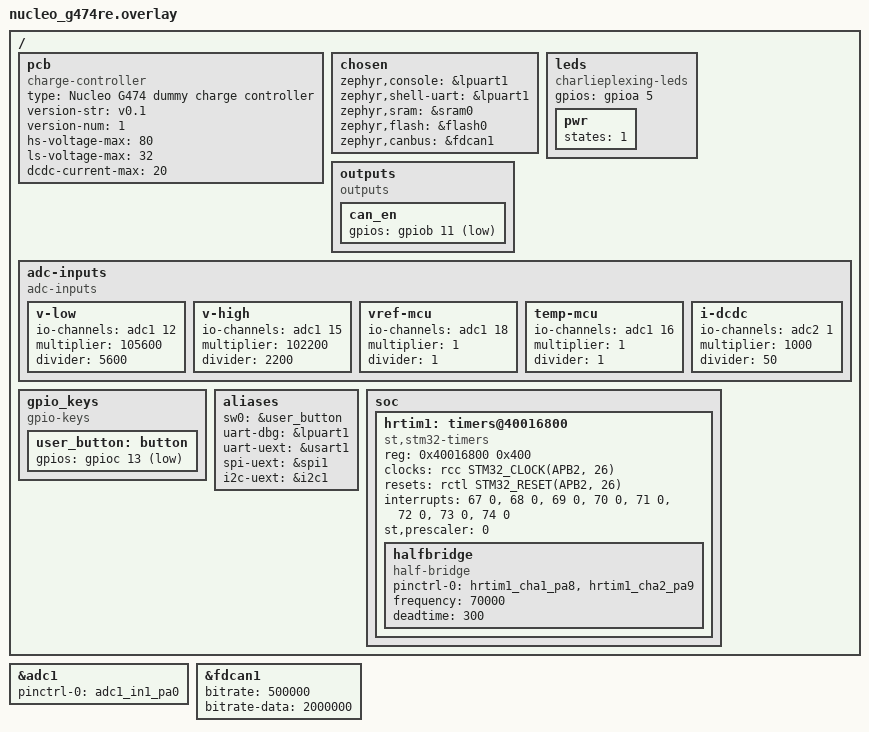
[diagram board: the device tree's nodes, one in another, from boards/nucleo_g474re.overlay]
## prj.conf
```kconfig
# Main application configuration (overrides board-specific settings)

# only very small heap necessary for malloc in printf statements with %f
CONFIG_HEAP_MEM_POOL_SIZE=256

CONFIG_CPP=y
CONFIG_REQUIRES_FULL_LIBCPP=y

CONFIG_PICOLIBC_IO_FLOAT=y

CONFIG_WATCHDOG=y
CONFIG_TASK_WDT=y
CONFIG_THREAD_NAME=y

CONFIG_REBOOT=y

CONFIG_HWINFO=y

CONFIG_CRC=y

CONFIG_CONSOLE_SUBSYS=y
CONFIG_CONSOLE_GETCHAR=y

# Use minimal logging by default to save memory for STM32F0 with little RAM
CONFIG_LOG=y
CONFIG_LOG_MODE_MINIMAL=y

CONFIG_THINGSET=y
CONFIG_THINGSET_SDK=y
CONFIG_THINGSET_STORAGE=y
CONFIG_THINGSET_SERIAL=y
CONFIG_THINGSET_STORAGE_DATA_VERSION=6
CONFIG_THINGSET_NODE_NAME="Libre Solar MPPT"

# Must be lower than LED thread to avoid flickering in boards with charlieplexing
CONFIG_THINGSET_SDK_THREAD_PRIORITY=6

# Uncomment to disable regular data publication on ThingSet serial at startup
#CONFIG_THINGSET_REPORTING_LIVE_ENABLE_PRESET=n

# Uncomment to enable I2C OLED display in UEXT connector
#CONFIG_UEXT_OLED_DISPLAY=y

# Select initial battery configuration: GEL (default), FLOODED, AGM, LFP, NMC or NMC_HV
#CONFIG_BAT_TYPE_???=y

# Change number of cells considering selected type (12V/24V battery by default if not set)
#CONFIG_BAT_NUM_CELLS=?
```

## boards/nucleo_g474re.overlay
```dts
/*
 * Copyright (c) 2019 STMicroelectronics.
 *
 * SPDX-License-Identifier: Apache-2.0
 */

/*
 * This is a dummy charge controller board for testing new features using the STM32G474 MCU
 *
 * IMPORTANT: You have to remove the VREF jumper on the Nucleo board to make it work. Otherwise
 *            the MCU will get stuck while trying to generate a reference voltage at VREF+ pin.
 */

/ {
	/* delete conflicting nodes from Zephyr board */
	/delete-node/ leds;
	/delete-node/ aliases;

	pcb {
		compatible = "charge-controller";

		type = "Nucleo G474 dummy charge controller";
		version-str = "v0.1";
		version-num = <1>;

		hs-voltage-max = <80>;
		ls-voltage-max = <32>;
		dcdc-current-max = <20>;
	};

	chosen {
		zephyr,console = &lpuart1;
		zephyr,shell-uart = &lpuart1;
		zephyr,sram = &sram0;
		zephyr,flash = &flash0;
		zephyr,canbus = &fdcan1;
	};

	leds {
		compatible = "charlieplexing-leds";
		gpios = <&gpioa 5 GPIO_ACTIVE_HIGH>;

		pwr {
			states = <1>;
		};
	};

	outputs {
		compatible = "outputs";

		can_en {
			gpios = <&gpiob 11 GPIO_ACTIVE_LOW>;
		};
	};

	adc-inputs {
		compatible = "adc-inputs";

		v-low {
			io-channels = <&adc1 12>;
			multiplier = <105600>;
			divider = <5600>;
		};

		v-high {
			io-channels = <&adc1 15>;
			multiplier = <102200>;
			divider = <2200>;
		};

		vref-mcu {
			io-channels = <&adc1 18>;
			multiplier = <1>;
			divider = <1>;
		};

		temp-mcu {
			io-channels = <&adc1 16>;
			multiplier = <1>;
			divider = <1>;
		};

		i-dcdc {
			io-channels = <&adc2 1>;
			// amp gain: 25, resistor: 2 mOhm
			multiplier = <1000>;	// 1000
			divider = <50>;	// 2*25
		};
	};

	gpio_keys {
		compatible = "gpio-keys";
		user_button: button {
			gpios = <&gpioc 13 GPIO_ACTIVE_LOW>;
		};
	};

	aliases {
		sw0 = &user_button;
		uart-dbg = &lpuart1;
		uart-uext = &usart1;
		spi-uext = &spi1;
		i2c-uext = &i2c1;
	};

	soc {
		hrtim1: timers@40016800 {
			compatible = "st,stm32-timers";
			reg = <0x40016800 0x400>;
			clocks = <&rcc STM32_CLOCK(APB2, 26)>;
			resets = <&rctl STM32_RESET(APB2, 26)>;
			interrupts = <67 0>, <68 0>, <69 0>, <70 0>,
				     <71 0>, <72 0>, <73 0>, <74 0>;
			interrupt-names = "master", "tima", "timb", "timc",
					  "timd", "time", "flt", "timf";
			st,prescaler = <0>;
			status = "disabled";
		};
	};
};

&hrtim1 {
	status = "okay";

	halfbridge: halfbridge {
		compatible = "half-bridge";
		pinctrl-0 = <&hrtim1_cha1_pa8 &hrtim1_cha2_pa9>;
		pinctrl-names = "default";
		frequency = <70000>;
		deadtime = <300>;
	};
};

/*
// alternative to HRTIM
&timers1 {
	status = "okay";

	halfbridge: halfbridge {
		compatible = "half-bridge";
		pinctrl-0 = <&tim1_ch1_pa8 &tim1_ch1n_pb13>;
		pinctrl-names = "default";
		frequency = <70000>;
		deadtime = <300>;
	};
};
*/

&adc1 {
	pinctrl-0 = <&adc1_in1_pa0>;
	pinctrl-names = "default";
	status = "okay";
};

&fdcan1 {
	bitrate = <500000>;
	bitrate-data = <2000000>;
	status = "okay";
};
```

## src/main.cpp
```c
/*
 * Copyright (c) The Libre Solar Project Contributors
 *
 * SPDX-License-Identifier: Apache-2.0
 */

#ifndef UNIT_TEST

#include <stdio.h>
#include <zephyr/device.h>
#include <zephyr/drivers/gpio.h>
#include <zephyr/kernel.h>
#include <zephyr/task_wdt/task_wdt.h>

#include "helper.h"
#include "setup.h"
#include "thingset.h" // handles access to internal data via communication interfaces

#include "bat_charger.h"   // battery settings and charger state machine
#include "daq.h"           // ADC using DMA and conversion to measurement values
#include "data_objects.h"  // for access to internal data via ThingSet
#include "data_storage.h"  // non-volatile data storage (e.g. EEPROM)
#include "dcdc.h"          // DC/DC converter control (hardware independent)
#include "device_status.h" // log data (error memory, min/max measurements, etc.)
#include "half_bridge.h"   // PWM generation for DC/DC converter
#include "hardware.h"   // hardware-related functions like load switch, LED control, watchdog, etc.
#include "leds.h"       // LED switching using charlieplexing
#include "load.h"       // load and USB output management
#include "pwm_switch.h" // PWM charge controller

int main(void)
{
    printf("Hardware: Libre Solar %s (%s)\n", DT_PROP(DT_PATH(pcb), type),
           DT_PROP(DT_PATH(pcb), version_str));
    printf("Firmware: %s\n", FIRMWARE_VERSION_ID);

    task_wdt_init(DEVICE_DT_GET_OR_NULL(DT_NODELABEL(iwdg)));

    setup();

    battery_conf_init(&bat_conf, CONFIG_BAT_TYPE, CONFIG_BAT_NUM_CELLS, CONFIG_BAT_CAPACITY_AH);
    battery_conf_overwrite(&bat_conf, &bat_conf_user); // initialize conf_user with same values

#if BOARD_HAS_DCDC
    daq_set_hv_limit(DT_PROP(DT_PATH(pcb), hs_voltage_max));
#endif

#if CONFIG_HV_TERMINAL_SOLAR || CONFIG_LV_TERMINAL_SOLAR || CONFIG_PWM_TERMINAL_SOLAR
    solar_terminal.init_solar();
#endif

#if CONFIG_HV_TERMINAL_NANOGRID
    grid_terminal.init_nanogrid();
#endif

    // read custom configuration from EEPROM
    data_objects_init();

    // Data Acquisition (DAQ) setup
    daq_setup();

    charger.detect_num_batteries(&bat_conf); // check if we have 24V instead of 12V system
    charger.init_terminal(&bat_conf);

#if BOARD_HAS_LOAD_OUTPUT
    load.set_voltage_limits(bat_conf.load_disconnect_voltage, bat_conf.load_reconnect_voltage,
                            bat_conf.absolute_max_voltage);
#endif

#if BOARD_HAS_USB_OUTPUT
    usb_pwr.set_voltage_limits(bat_conf.load_disconnect_voltage - 0.1f, // keep on longer than load
                               bat_conf.load_reconnect_voltage, bat_conf.absolute_max_voltage);
#endif

    // wait until all threads are spawned before activating the watchdog
    k_sleep(K_MSEC(2500));

    int64_t t_start = k_uptime_get();

    while (true) {
        // loop runs exactly once per second and includes slow control tasks and energy calculation

        charger.discharge_control(&bat_conf);
        charger.charge_control(&bat_conf);

// energy + soc calculation must be called exactly once per second
#if BOARD_HAS_DCDC
        if (dcdc.state != DCDC_CONTROL_OFF) {
            hv_terminal.energy_balance();
        }
#endif

#if BOARD_HAS_PWM_PORT
        if (pwm_switch.active() == 1) {
            pwm_switch.energy_balance();
        }
#endif

        lv_terminal.energy_balance();

#if BOARD_HAS_LOAD_OUTPUT
        if (load.state == 1) {
            load.energy_balance();
        }
#endif

        dev_stat.update_energy();
        dev_stat.update_min_max_values();
        charger.update_soc(&bat_conf);

#if CONFIG_HS_MOSFET_FAIL_SAFE_PROTECTION && BOARD_HAS_DCDC
        if (dev_stat.has_error(ERR_DCDC_HS_MOSFET_SHORT)) {
            dcdc.fuse_destruction();
        }
#endif

        leds_update_1s();

#if BOARD_HAS_LOAD_OUTPUT
        leds_update_soc(charger.soc, flags_check(&load.error_flags, ERR_LOAD_SHEDDING));
#else
        leds_update_soc(charger.soc, false);
#endif

        data_storage_update();

        t_start += 1000;
        k_sleep(K_TIMEOUT_ABS_MS(t_start));
    }
}

void control_thread()
{
    int wdt_channel = task_wdt_add(200, task_wdt_callback, (void *)k_current_get());

    while (true) {
        // control loop runs at approx. 10 Hz

        bool charging = false;

        task_wdt_feed(wdt_channel);

        // convert ADC readings to meaningful measurement values
        daq_update();

        // alerts should trigger only for transients, so update based on actual voltage
        daq_set_lv_limits(lv_terminal.bus->voltage * 1.2F, lv_terminal.bus->voltage * 0.8F);

        lv_terminal.update_bus_current_margins();

#if BOARD_HAS_PWM_PORT
        pwm_switch.control();
        charging |= pwm_switch.active();
#endif

#if BOARD_HAS_DCDC
        hv_terminal.update_bus_current_margins();
        dcdc.control(); // control of DC/DC including MPPT algorithm
        charging |= half_bridge_enabled();
#endif

        leds_set_charging(charging);

#if BOARD_HAS_LOAD_OUTPUT
        load.control();
#endif

#if BOARD_HAS_USB_OUTPUT
        usb_pwr.control();
#endif

        k_sleep(K_MSEC(100));
    }
}

// 2s delay for control thread as a safety feature: be able to re-flash before starting
// priority is set to -1 (=cooperative) to have higher priority than other threads incl. main
K_THREAD_DEFINE(control_thread_id, 1024, control_thread, NULL, NULL, NULL, -1, 0, 2000);

#endif // UNIT_TEST
```

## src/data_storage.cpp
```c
/*
 * Copyright (c) The Libre Solar Project Contributors
 *
 * SPDX-License-Identifier: Apache-2.0
 */

#include "data_storage.h"

#include <zephyr/kernel.h>

#include "data_objects.h"
#include "helper.h"
#include "mcu.h"
#include "thingset.h"
#include "zephyr/toolchain.h"

#include <stdio.h>

#ifdef CONFIG_SOC_FAMILY_STM32

#include <stm32_ll_bus.h>
#include <zephyr/device.h>

LOG_MODULE_REGISTER(nvs, CONFIG_DATA_STORAGE_LOG_LEVEL);

K_MUTEX_DEFINE(data_buf_lock);

// Buffer used by store and restore functions (must be word-aligned for hardware CRC calculation)
__maybe_unused static uint8_t buf[512] __aligned(sizeof(uint32_t));

extern ThingSet ts;

uint32_t _calc_crc(const uint8_t *buf, size_t len)
{
    LL_AHB1_GRP1_EnableClock(LL_AHB1_GRP1_PERIPH_CRC);

    // we keep standard polynomial 0x04C11DB7 (same for STM32L0 and STM32F0)
    // and we don't care for endianness here
    CRC->CR |= CRC_CR_RESET;
    for (size_t i = 0; i < len; i += 4) {
        // printf("CRC buf: %.8x, CRC->DR: %.8x\n", *((uint32_t*)&buf[i]), CRC->DR);
        size_t remaining_bytes = len - i;
        if (remaining_bytes >= 4) {
            CRC->DR = *((uint32_t *)&buf[i]);
        }
        else {
            // ignore bytes >= len if len is not a multiple of 4
            CRC->DR = *((uint32_t *)&buf[i]) & (0xFFFFFFFFU >> (32 - remaining_bytes * 8));
        }
    }

    LL_AHB1_GRP1_DisableClock(LL_AHB1_GRP1_PERIPH_CRC);

    return CRC->DR;
}

#endif /* UNIT_TEST */

#ifdef CONFIG_EEPROM

#include <zephyr/drivers/eeprom.h>

/*
 * EEPROM header bytes:
 * - 0-1: Data objects version number
 * - 2-3: Number of data bytes
 * - 4-7: CRC32
 *
 * Data starts from byte 8
 */
#define EEPROM_HEADER_SIZE 8

static const struct device *eeprom_dev = DEVICE_DT_GET(DT_NODELABEL(eeprom));

void data_storage_read()
{
    int err;

    if (!device_is_ready(eeprom_dev)) {
        LOG_ERR("EEPROM device not ready");
        return;
    }

    uint8_t buf_header[EEPROM_HEADER_SIZE] = {};
    err = eeprom_read(eeprom_dev, 0, buf_header, EEPROM_HEADER_SIZE);
    if (err != 0) {
        LOG_ERR("EEPROM read error %d", err);
        return;
    }
    uint16_t version = *((uint16_t *)&buf_header[0]);
    uint16_t len = *((uint16_t *)&buf_header[2]);
    uint32_t crc = *((uint32_t *)&buf_header[4]);

    LOG_DBG("EEPROM header restore: ver %d, len %d, CRC %.8x", version, len, (unsigned int)crc);
    LOG_DBG("Header: %.2x %.2x %.2x %.2x %.2x %.2x %.2x %.2x", buf_header[0], buf_header[1],
            buf_header[2], buf_header[3], buf_header[4], buf_header[5], buf_header[6],
            buf_header[7]);

    if (version == DATA_OBJECTS_VERSION && len <= sizeof(buf)) {
        k_mutex_lock(&data_buf_lock, K_FOREVER);
        err = eeprom_read(eeprom_dev, EEPROM_HEADER_SIZE, buf, len);

        // printf("Data (len=%d): ", len);
        // for (int i = 0; i < len; i++) printf("%.2x ", buf[i]);

        if (_calc_crc(buf, len) == crc) {
            int status = ts.bin_import(buf, sizeof(buf), TS_WRITE_MASK, SUBSET_NVM);
            LOG_INF("EEPROM read and data objects updated, ThingSet result: 0x%x", status);
        }
        else {
            LOG_ERR("EEPROM data CRC invalid, expected 0x%x (data_len = %d)", (unsigned int)crc,
                    len);
        }
        k_mutex_unlock(&data_buf_lock);
    }
    else {
        LOG_INF("EEPROM empty or data layout version changed");
    }
}

void data_storage_write()
{
    int err;

    if (!device_is_ready(eeprom_dev)) {
        LOG_ERR("EEPROM device not ready");
        return;
    }

    k_mutex_lock(&data_buf_lock, K_FOREVER);

    int len = ts.bin_export(buf + EEPROM_HEADER_SIZE, sizeof(buf) - EEPROM_HEADER_SIZE, SUBSET_NVM);
    uint32_t crc = _calc_crc(buf + EEPROM_HEADER_SIZE, len);

    *((uint16_t *)&buf[0]) = (uint16_t)DATA_OBJECTS_VERSION;
    *((uint16_t *)&buf[2]) = (uint16_t)(len);
    *((uint32_t *)&buf[4]) = crc;

    // printf("Data (len=%d): ", len);
    // for (int i = 0; i < len; i++) printf("%.2x ", buf[i + EEPROM_HEADER_SIZE]);

    LOG_DBG("Header: %.2x %.2x %.2x %.2x %.2x %.2x %.2x %.2x", buf[0], buf[1], buf[2], buf[3],
            buf[4], buf[5], buf[6], buf[7]);

    if (len == 0) {
        LOG_ERR("EEPROM data could not be stored. ThingSet error (len = %d)", len);
    }
    else {
        err = eeprom_write(eeprom_dev, 0, buf, len + EEPROM_HEADER_SIZE);
        if (err == 0) {
            LOG_INF("EEPROM data successfully stored");
        }
        else {
            LOG_ERR("EEPROM write error %d", err);
        }
    }
    k_mutex_unlock(&data_buf_lock);
}

#elif defined(CONFIG_NVS)

#include <zephyr/drivers/flash.h>
#include <zephyr/fs/nvs.h>
#include <zephyr/storage/flash_map.h>

/*
 * NVS header bytes:
 * - 0-1: Data objects version number
 *
 * Data starts from byte 2
 */
#define NVS_HEADER_SIZE 2

#define NVS_PARTITION storage_partition

#define THINGSET_DATA_ID 1

static struct nvs_fs fs;
static bool nvs_initialized = false;

static int data_storage_init()
{
    int err;
    struct flash_pages_info page_info;

    fs.flash_device = FIXED_PARTITION_DEVICE(NVS_PARTITION);
    if (!device_is_ready(fs.flash_device)) {
        LOG_ERR("Flash device not ready");
        return -ENODEV;
    }
    fs.offset = FIXED_PARTITION_OFFSET(NVS_PARTITION);
    err = flash_get_page_info_by_offs(fs.flash_device, fs.offset, &page_info);
    if (err) {
        LOG_ERR("Unable to get flash page info");
        return err;
    }
    fs.sector_size = page_info.size;
    fs.sector_count = FIXED_PARTITION_SIZE(NVS_PARTITION) / page_info.size;

    err = nvs_mount(&fs);
    if (err) {
        LOG_ERR("NVS mount failed: %d", err);
        return err;
    }

    nvs_initialized = true;
    return 0;
}

void data_storage_read()
{
    if (!nvs_initialized) {
        int err = data_storage_init();
        if (err) {
            return;
        }
    }

    int num_bytes = nvs_read(&fs, THINGSET_DATA_ID, &buf, sizeof(buf));

    if (num_bytes < 0) {
        LOG_INF("NVS empty (read error %d)", num_bytes);
        return;
    }

    uint16_t version = *((uint16_t *)&buf[0]);

    if (version == DATA_OBJECTS_VERSION) {
        k_mutex_lock(&data_buf_lock, K_FOREVER);

        int status = ts.bin_import(buf + NVS_HEADER_SIZE, num_bytes - NVS_HEADER_SIZE,
                                   TS_WRITE_MASK, SUBSET_NVM);
        LOG_INF("NVS read and data objects updated, ThingSet result: 0x%x", status);

        k_mutex_unlock(&data_buf_lock);
    }
    else {
        LOG_INF("NVS data layout version changed");
    }
}

void data_storage_write()
{
    if (!nvs_initialized) {
        int err = data_storage_init();
        if (err) {
            return;
        }
    }

    k_mutex_lock(&data_buf_lock, K_FOREVER);

    *((uint16_t *)&buf[0]) = (uint16_t)DATA_OBJECTS_VERSION;

    int len = ts.bin_export(buf + NVS_HEADER_SIZE, sizeof(buf) - NVS_HEADER_SIZE, SUBSET_NVM);

    if (len == 0) {
        LOG_ERR("NVS data could not be stored. ThingSet error (len = %d)", len);
    }
    else {
        int ret = nvs_write(&fs, THINGSET_DATA_ID, &buf, len + NVS_HEADER_SIZE);
        if (ret == len + NVS_HEADER_SIZE) {
            LOG_DBG("NVS data successfully stored");
        }
        else if (ret == 0) {
            LOG_DBG("NVS data unchanged");
        }
        else {
            LOG_ERR("NVS write error %d", ret);
        }
    }

    k_mutex_unlock(&data_buf_lock);
}

#else

void data_storage_write()
{}
void data_storage_read()
{}

#endif

void data_storage_update()
{
    if (uptime() % DATA_UPDATE_INTERVAL == 0 && uptime() > 0) {
        data_storage_write();
    }
}
```

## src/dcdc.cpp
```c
/*
 * Copyright (c) The Libre Solar Project Contributors
 *
 * SPDX-License-Identifier: Apache-2.0
 */

#include "dcdc.h"

#include <zephyr/kernel.h>

#include <zephyr/device.h>
#include <zephyr/drivers/gpio.h>

#include <math.h> // for fabs function
#include <stdio.h>
#include <stdlib.h> // for min/max function

#include "data_storage.h"
#include "device_status.h"
#include "half_bridge.h"
#include "helper.h"
#include "setup.h"

LOG_MODULE_REGISTER(dcdc, CONFIG_DCDC_LOG_LEVEL);

#if BOARD_HAS_DCDC

#define BUCK_DUTY_POWER_DECREASE (-1)
#define BUCK_DUTY_POWER_INCREASE (1)

#define BOOST_DUTY_POWER_DECREASE (1)
#define BOOST_DUTY_POWER_INCREASE (-1)

#ifdef CONFIG_SOC_SERIES_STM32G4X
#define DUTY_STEP_SIZE (3) // increased step size for fast microcontroller
#else
#define DUTY_STEP_SIZE (1) // single minimum step for other microcontrollers
#endif

#if DT_NODE_EXISTS(DT_CHILD(DT_PATH(outputs), hv_out))
#define HV_OUT_NODE DT_CHILD(DT_PATH(outputs), hv_out)
#endif

extern DeviceStatus dev_stat;

Dcdc::Dcdc(DcBus *high, DcBus *low, DcdcOperationMode op_mode)
{
    hvb = high;
    lvb = low;
    mode = op_mode;
    enable = true;
    state = DCDC_CONTROL_OFF;
    inductor_current_max = DT_PROP(DT_PATH(pcb), dcdc_current_max);
    hs_voltage_max = DT_PROP(DT_PATH(pcb), hs_voltage_max);
    ls_voltage_max = DT_PROP(DT_PATH(pcb), ls_voltage_max);
    ls_voltage_min = 9.0;
    output_power_min = 1; // switch off if power < 1 W
    restart_interval = 60;
    off_timestamp = -10000; // start immediately

    // lower duty limit might have to be adjusted dynamically depending on LS voltage
    half_bridge_init(DT_PROP(DT_INST(0, half_bridge), frequency) / 1000,
                     DT_PROP(DT_INST(0, half_bridge), deadtime), 12 / hs_voltage_max, 0.97);
}

void Dcdc::perturb_observe_buck()
{
    if (power >= output_power_min) {
        power_good_timestamp = uptime();
    }

    if ((uptime() - power_good_timestamp > 10 || power < -10.0f) && mode != DCDC_MODE_AUTO) {
        // switch off after 10s low power or negative power (if not in nanogrid mode)
        pwm_direction = 0;
    }
    else if (lvb->voltage > lvb->sink_control_voltage()) {
        state = DCDC_CONTROL_CV_LS;
        pwm_direction = BUCK_DUTY_POWER_DECREASE;
    }
    else if (lvb->sink_current_margin < 0 || inductor_current > inductor_current_max) {
        state = DCDC_CONTROL_CC_LS;
        pwm_direction = BUCK_DUTY_POWER_DECREASE;
    }
    else if (hvb->src_current_margin > 0) {
        state = DCDC_CONTROL_CC_HS;
        pwm_direction = BUCK_DUTY_POWER_DECREASE;
    }
    else if (hvb->voltage < hvb->src_control_voltage() && power > output_power_min) {
        // input voltage below limit
        state = DCDC_CONTROL_CV_HS;
        pwm_direction = BUCK_DUTY_POWER_DECREASE;
    }
    else if (temp_mosfets > DCDC_MOSFETS_MAX_TEMP) {
        state = DCDC_CONTROL_DERATING;
        pwm_direction = BUCK_DUTY_POWER_DECREASE;
    }
    else if (power < output_power_min && lvb->voltage < lvb->src_control_voltage()) {
        // no load condition (e.g. start-up of nanogrid) --> raise voltage
        pwm_direction = BUCK_DUTY_POWER_INCREASE;
    }
    else {
        state = DCDC_CONTROL_MPPT;
        if (power_prev > power) {
            pwm_direction = -pwm_direction;
        }
    }

    power_prev = power;
}

void Dcdc::perturb_observe_boost()
{
    if (-power >= output_power_min) {
        power_good_timestamp = uptime();
    }

    if ((uptime() - power_good_timestamp > 10 || -power < -10.0f) && mode != DCDC_MODE_AUTO) {
        // switch off after 10s low power or negative power (if not in nanogrid mode)
        pwm_direction = 0;
    }
    else if (hvb->voltage > hvb->sink_control_voltage()) {
        state = DCDC_CONTROL_CV_HS;
        pwm_direction = BOOST_DUTY_POWER_DECREASE;
    }
    else if (hvb->sink_current_margin < 0) {
        state = DCDC_CONTROL_CC_HS;
        pwm_direction = BOOST_DUTY_POWER_DECREASE;
    }
    else if (lvb->src_current_margin > 0 || -inductor_current > inductor_current_max) {
        state = DCDC_CONTROL_CC_LS;
        pwm_direction = BOOST_DUTY_POWER_DECREASE;
    }
    else if (lvb->voltage < lvb->src_control_voltage() && -power > output_power_min) {
        // input voltage below limit
        state = DCDC_CONTROL_CV_LS;
        pwm_direction = BOOST_DUTY_POWER_DECREASE;
    }
    else if (temp_mosfets > DCDC_MOSFETS_MAX_TEMP) {
        state = DCDC_CONTROL_DERATING;
        pwm_direction = BOOST_DUTY_POWER_DECREASE;
    }
    else if (-power < output_power_min && hvb->voltage < hvb->src_control_voltage()) {
        // no load condition (e.g. start-up of nanogrid) --> raise voltage
        pwm_direction = BOOST_DUTY_POWER_INCREASE;
    }
    else {
        state = DCDC_CONTROL_MPPT;
        if (-power_prev > -power) {
            pwm_direction = -pwm_direction;
        }
    }

    power_prev = power;
}

__weak DcdcOperationMode Dcdc::check_start_conditions()
{
    if (enable == false
        || hvb->voltage > hs_voltage_max // also critical for buck mode because of ringing
        || lvb->voltage > ls_voltage_max || lvb->voltage < ls_voltage_min
        || dev_stat.has_error(ERR_BAT_UNDERVOLTAGE | ERR_BAT_OVERVOLTAGE)
        || (int)uptime() < (off_timestamp + (int)restart_interval))
    {
        return DCDC_MODE_OFF;
    }

    if (lvb->sink_current_margin > 0 && lvb->voltage < lvb->sink_control_voltage()
        && hvb->src_current_margin < 0 && hvb->voltage > hvb->src_control_voltage()
        && hvb->voltage * 0.85f > lvb->voltage)
    {
        return DCDC_MODE_BUCK;
    }

    if (hvb->sink_current_margin > 0 && hvb->voltage < hvb->sink_control_voltage()
        && lvb->src_current_margin < 0 && lvb->voltage > lvb->src_control_voltage())
    {
        return DCDC_MODE_BOOST;
    }

    return DCDC_MODE_OFF;
}

bool Dcdc::check_hs_mosfet_short()
{
    static uint32_t first_time_detected;
    if (half_bridge_enabled() == false && inductor_current > 0.5F
        && lvb->voltage_filtered > lvb->sink_control_voltage())
    {
        // if there is current even though the DC/DC is switched off, the
        // high-side MOSFET must be broken --> set flag and let main() decide
        // what to do... (e.g. call dcdc_self_destruction)

        uint32_t now = uptime();
        if (first_time_detected == 0) {
            first_time_detected = now;
        }
        else if (now - first_time_detected > 10) {
            // waited approx 10s before setting the flag
            dev_stat.set_error(ERR_DCDC_HS_MOSFET_SHORT);
        }
    }
    else {
        first_time_detected = 0;
    }

    return dev_stat.has_error(ERR_DCDC_HS_MOSFET_SHORT);
}

bool Dcdc::startup_inhibit(bool reset)
{
    static uint32_t inhibit_start;

    if (reset) {
        inhibit_start = uptime();
        return true;
    }
    else {
        return (uptime() < inhibit_start + DCDC_STARTUP_INHIBIT_TIME);
    }
}

__weak void Dcdc::control()
{
    if (half_bridge_enabled() == false) {

        if (check_hs_mosfet_short()) {
            return;
        }

        int startup_mode = check_start_conditions();

        if ((startup_mode == DCDC_MODE_BUCK && mode == DCDC_MODE_BUCK)
            || (startup_mode == DCDC_MODE_BOOST && mode == DCDC_MODE_BOOST)
            || (startup_mode != DCDC_MODE_OFF && mode == DCDC_MODE_AUTO))
        {
            output_hvs_enable();

            // startup allowed, but we need to wait until voltages settle
            if (startup_inhibit()) {
                return;
            }

            const char *mode_name = NULL;
            if (startup_mode == DCDC_MODE_BUCK) {
                mode_name = "buck";
                pwm_direction = BUCK_DUTY_POWER_INCREASE;
                // Don't start directly at Vmpp (approx. 0.8 * Voc) to prevent high inrush
                // currents and stress on MOSFETs
                half_bridge_set_duty_cycle(lvb->voltage / (hvb->voltage - 1));
            }
            else {
                mode_name = "boost";
                pwm_direction = BOOST_DUTY_POWER_INCREASE;
                // Will automatically start with max. duty (0.97) if connected to a
                // nanogrid not yet started up (zero voltage)
                half_bridge_set_duty_cycle(lvb->voltage / (hvb->voltage + 1));
            }

            half_bridge_start();
            power_good_timestamp = uptime();
            printf("DC/DC %s mode start (HV: %.2fV, LV: %.2fV, PWM: %.1f).\n", mode_name,
                   (double)hvb->voltage, (double)lvb->voltage,
                   (double)half_bridge_get_duty_cycle() * 100.0);
        }
        else {
            startup_inhibit(true); // reset inhibit counter
        }
    }
    else { // half bridge is on

        const char *stop_reason = NULL;
        if (lvb->voltage > ls_voltage_max || hvb->voltage > hs_voltage_max) {
            stop_reason = "emergency (voltage limits exceeded)";
        }
        else if (enable == false) {
            stop_reason = "disabled";
        }
        else {
            if (mode == DCDC_MODE_BUCK || (mode == DCDC_MODE_AUTO && inductor_current > 0.1f)) {
                perturb_observe_buck();
            }
            else {
                perturb_observe_boost();
            }

            if (pwm_direction != 0) {
                half_bridge_set_ccr(half_bridge_get_ccr() + pwm_direction * DUTY_STEP_SIZE);

                // requires floating point support with CONFIG_CBPRINTF_FP_SUPPORT=y
                LOG_DBG("P %.2fW, inductor %.2fA, HS: %.2fV, %.2fA margin, "
                        "LS: %.2fV (target %.2fV), %.2fA margin, "
                        "PWM: %.1f, dcdc_state: %d, pwm_direction: %d",
                        (double)power, (double)inductor_current, (double)hvb->voltage,
                        (double)hvb->src_current_margin, (double)lvb->voltage,
                        (double)lvb->sink_voltage_intercept, (double)lvb->sink_current_margin,
                        (double)half_bridge_get_duty_cycle() * 100.0, state, pwm_direction);
            }
            else {
                stop_reason = "low power";
            }
        }

        if (stop_reason != NULL) {
            stop();
            printf("DC/DC Stop: %s.\n", stop_reason);
        }
    }
}

void Dcdc::test()
{
    if (half_bridge_enabled()) {
        const char *stop_reason = NULL;
        if (lvb->voltage > ls_voltage_max || hvb->voltage > hs_voltage_max) {
            stop_reason = "emergency (voltage limits exceeded)";
        }
        else if (enable == false) {
            stop_reason = "disabled";
        }
        else {
            if (half_bridge_get_duty_cycle() > 0.50f) {
                half_bridge_set_ccr(half_bridge_get_ccr() - 1);
            }
            else {
                half_bridge_set_ccr(half_bridge_get_ccr() + 1);
            }
        }
        if (stop_reason != NULL) {
            stop();
            printf("DC/DC Stop: %s.\n", stop_reason);
        }
    }
    else {
        if (check_start_conditions() != DCDC_MODE_OFF) {
            // startup allowed, but we need to wait until voltages settle
            if (startup_inhibit()) {
                return;
            }

            half_bridge_set_duty_cycle(lvb->voltage / hvb->voltage);
            half_bridge_start();
            printf("DC/DC test mode start (HV: %.2fV, LV: %.2fV, PWM: %.1f).\n",
                   (double)hvb->voltage, (double)lvb->voltage,
                   (double)half_bridge_get_duty_cycle() * 100.0);
        }
        else {
            startup_inhibit(true); // reset inhibit counter
        }
    }
}

void Dcdc::stop()
{
    half_bridge_stop();
    state = DCDC_CONTROL_OFF;
    off_timestamp = uptime();
    output_hvs_disable();
}

void Dcdc::fuse_destruction()
{
    static int counter = 0;

    if (counter > 20) { // wait 20s to be able to send out data
        LOG_ERR("Charge controller fuse destruction called!\n");
        data_storage_write();
        half_bridge_stop();
        half_bridge_init(50, 0, 0, 0.98); // reset safety limits to allow 0% duty cycle
        half_bridge_set_duty_cycle(0);
        half_bridge_start();
        // now the fuse should be triggered and we disappear
    }
    counter++;
}

void Dcdc::output_hvs_enable()
{
#ifdef HV_OUT_NODE
    const struct device *hv_out = DEVICE_DT_GET(DT_GPIO_CTLR(HV_OUT_NODE, gpios));
    if (device_is_ready(hv_out)) {
        gpio_pin_configure(hv_out, DT_GPIO_PIN(HV_OUT_NODE, gpios),
                           DT_GPIO_FLAGS(HV_OUT_NODE, gpios) | GPIO_OUTPUT_ACTIVE);
    }
#endif
}

void Dcdc::output_hvs_disable()
{
#ifdef HV_OUT_NODE
    const struct device *hv_out = DEVICE_DT_GET(DT_GPIO_CTLR(HV_OUT_NODE, gpios));
    if (device_is_ready(hv_out)) {
        gpio_pin_configure(hv_out, DT_GPIO_PIN(HV_OUT_NODE, gpios),
                           DT_GPIO_FLAGS(HV_OUT_NODE, gpios) | GPIO_OUTPUT_INACTIVE);
    }
#endif
}

#else

Dcdc::Dcdc(DcBus *high, DcBus *low, DcdcOperationMode op_mode)
{}

#endif /* BOARD_HAS_DCDC */
```
